VERSION ""

NS_ :

BS_:

BU_: ECU2 ECU1

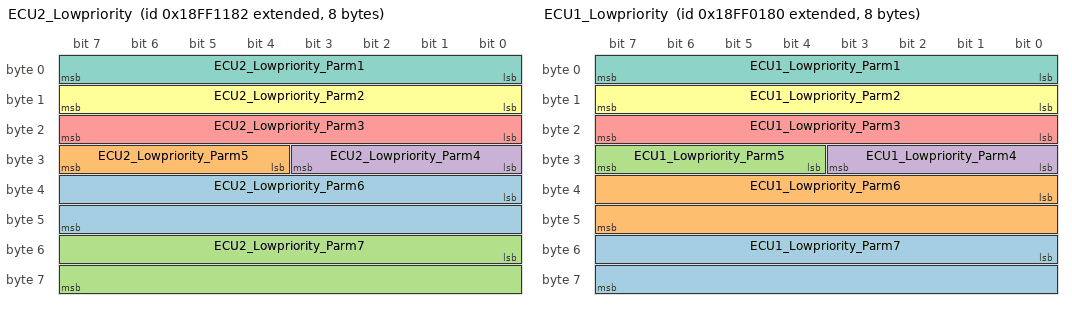
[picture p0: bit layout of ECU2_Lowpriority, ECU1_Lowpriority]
BO_ 2566852994 ECU2_Lowpriority: 8 ECU2
 SG_ ECU2_Lowpriority_Parm6 : 32|16@1- (1,0) [0|0] "" Vector__XXX
 SG_ ECU2_Lowpriority_Parm5 : 28|4@1- (1,0) [0|0] "" Vector__XXX
 SG_ ECU2_Lowpriority_Parm7 : 48|16@1- (1,0) [0|0] "" Vector__XXX
 SG_ ECU2_Lowpriority_Parm4 : 24|4@1- (1,0) [0|0] "" Vector__XXX
 SG_ ECU2_Lowpriority_Parm3 : 16|8@1- (1,0) [0|0] "" Vector__XXX
 SG_ ECU2_Lowpriority_Parm2 : 8|8@1- (1,0) [0|0] "" Vector__XXX
 SG_ ECU2_Lowpriority_Parm1 : 0|8@1- (1,0) [0|0] "" Vector__XXX

BO_ 2566848896 ECU1_Lowpriority: 8 ECU1
 SG_ ECU1_Lowpriority_Parm7 : 48|16@1- (1,0) [0|0] "" Vector__XXX
 SG_ ECU1_Lowpriority_Parm6 : 32|16@1- (1,0) [0|0] "" Vector__XXX
 SG_ ECU1_Lowpriority_Parm5 : 28|4@1- (1,0) [0|0] "" Vector__XXX
 SG_ ECU1_Lowpriority_Parm4 : 24|4@1- (1,0) [0|0] "" Vector__XXX
 SG_ ECU1_Lowpriority_Parm3 : 16|8@1- (1,0) [0|0] "" Vector__XXX
 SG_ ECU1_Lowpriority_Parm2 : 8|8@1- (1,0) [0|0] "" Vector__XXX
 SG_ ECU1_Lowpriority_Parm1 : 0|8@1- (1,0) [0|0] "" Vector__XXX

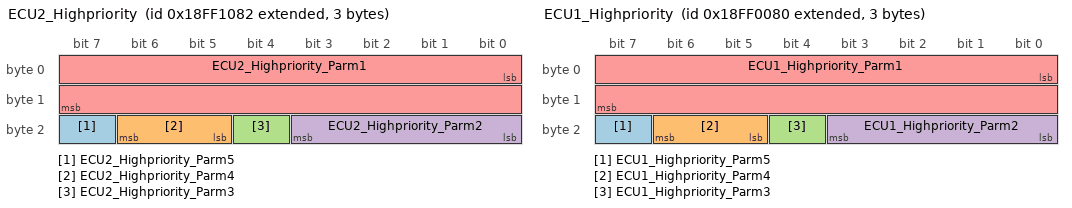
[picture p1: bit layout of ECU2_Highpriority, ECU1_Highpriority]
BO_ 2566852738 ECU2_Highpriority: 3 ECU2
 SG_ ECU2_Highpriority_Parm5 : 23|1@1- (1,0) [0|0] "" Vector__XXX
 SG_ ECU2_Highpriority_Parm4 : 21|2@1- (1,0) [0|0] "" Vector__XXX
 SG_ ECU2_Highpriority_Parm3 : 20|1@1- (1,0) [0|0] "" Vector__XXX
 SG_ ECU2_Highpriority_Parm2 : 16|4@1- (1,0) [0|0] "" Vector__XXX
 SG_ ECU2_Highpriority_Parm1 : 0|16@1- (1,0) [0|0] "" Vector__XXX

BO_ 2566848640 ECU1_Highpriority: 3 ECU1
 SG_ ECU1_Highpriority_Parm5 : 23|1@1- (1,0) [0|0] "" Vector__XXX
 SG_ ECU1_Highpriority_Parm4 : 21|2@1- (1,0) [0|0] "" Vector__XXX
 SG_ ECU1_Highpriority_Parm3 : 20|1@1- (1,0) [0|0] "" Vector__XXX
 SG_ ECU1_Highpriority_Parm2 : 16|4@1- (1,0) [0|0] "" Vector__XXX
 SG_ ECU1_Highpriority_Parm1 : 0|16@1- (1,0) [0|0] "" Vector__XXX

BA_DEF_ SG_  "SigType" ENUM  "Default","Range","RangeSigned","ASCII","Discrete","Control","ReferencePGN","DTC","StringDelimiter","StringLength","StringLengthControl","MessageCounter","MessageChecksum";
BA_DEF_ SG_  "GenSigEVName" STRING ;
BA_DEF_ SG_  "GenSigILSupport" ENUM  "No","Yes";
BA_DEF_ SG_  "GenSigSendType" ENUM  "Cyclic","OnWrite","OnWriteWithRepetition","OnChange","OnChangeWithRepetition","IfActive","IfActiveWithRepetition","NoSigSendType";
BA_DEF_ BO_  "GenMsgILSupport" ENUM  "No","Yes";
BA_DEF_ BU_  "NmStationAddress" INT 0 255;
BA_DEF_ BO_  "GenMsgSendType" ENUM  "cyclic","NotUsed","IfActive","NotUsed","NotUsed","NotUsed","NotUsed","NotUsed","noMsgSendType";
BA_DEF_ BO_  "GenMsgRequestable" INT 0 1;
BA_DEF_ BO_  "GenMsgCycleTime" INT 0 3600000;
BA_DEF_  "DBName" STRING ;
BA_DEF_  "BusType" STRING ;
BA_DEF_  "ProtocolType" STRING ;
BA_DEF_ BO_  "VFrameFormat" ENUM  "StandardCAN","ExtendedCAN","reserved","J1939PG";
BA_DEF_DEF_  "SigType" "Default";
BA_DEF_DEF_  "GenSigEVName" "Env@Nodename_@Signame";
BA_DEF_DEF_  "GenSigILSupport" "Yes";
BA_DEF_DEF_  "GenSigSendType" "NoSigSendType";
BA_DEF_DEF_  "GenMsgILSupport" "Yes";
BA_DEF_DEF_  "NmStationAddress" 254;
BA_DEF_DEF_  "GenMsgSendType" "noMsgSendType";
BA_DEF_DEF_  "GenMsgRequestable" 1;
BA_DEF_DEF_  "GenMsgCycleTime" 0;
BA_DEF_DEF_  "DBName" "";
BA_DEF_DEF_  "BusType" "CAN";
BA_DEF_DEF_  "ProtocolType" "J1939";
BA_DEF_DEF_  "VFrameFormat" "J1939PG";
BA_ "DBName" "J1939_Database";
BA_ "NmStationAddress" BU_ ECU2 130;
BA_ "NmStationAddress" BU_ ECU1 128;
BA_ "GenMsgCycleTime" BO_ 2566848896 100;
BA_ "GenMsgCycleTime" BO_ 2566852738 20;
BA_ "GenMsgCycleTime" BO_ 2566848640 20;
